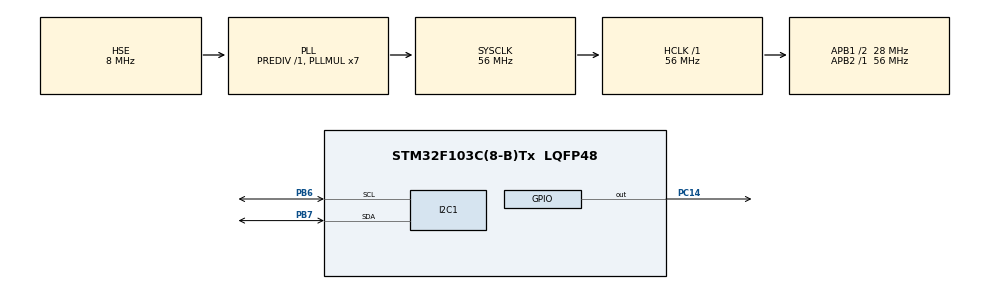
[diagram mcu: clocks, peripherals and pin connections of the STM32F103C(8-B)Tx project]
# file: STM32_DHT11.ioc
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Mcu.Family=STM32F1
Mcu.Name=STM32F103C(8-B)Tx
Mcu.Package=LQFP48
NVIC.PriorityGroup=NVIC_PRIORITYGROUP_4
PA13.Mode=Serial_Wire
PA13.Signal=SYS_JTMS-SWDIO
PA14.Mode=Serial_Wire
PA14.Signal=SYS_JTCK-SWCLK
PB6.Mode=I2C
PB6.Signal=I2C1_SCL
PB7.Mode=I2C
PB7.Signal=I2C1_SDA
PC14-OSC32_IN.GPIO_Speed=GPIO_SPEED_FREQ_HIGH
PC14-OSC32_IN.Signal=GPIO_Output
PD0-OSC_IN.Mode=HSE-External-Oscillator
PD0-OSC_IN.Signal=RCC_OSC_IN
PD1-OSC_OUT.Mode=HSE-External-Oscillator
PD1-OSC_OUT.Signal=RCC_OSC_OUT
ProjectManager.HeapSize=0x200
ProjectManager.StackSize=0x400
ProjectManager.TargetToolchain=MDK-ARM V5.27
RCC.AHBFreq_Value=56000000
RCC.APB1CLKDivider=RCC_HCLK_DIV2
RCC.APB1Freq_Value=28000000
RCC.APB1TimFreq_Value=56000000
RCC.APB2Freq_Value=56000000
RCC.APB2TimFreq_Value=56000000
RCC.HCLKFreq_Value=56000000
RCC.PLLMUL=RCC_PLL_MUL7
RCC.PLLSourceVirtual=RCC_PLLSOURCE_HSE
RCC.SYSCLKFreq_VALUE=56000000
RCC.SYSCLKSource=RCC_SYSCLKSOURCE_PLLCLK
RCC.USBFreq_Value=56000000
TIM2.AutoReloadPreload=TIM_AUTORELOAD_PRELOAD_DISABLE
TIM2.Period=0xFFFF
TIM2.Prescaler=56-1
VP_TIM2_VS_ClockSourceINT.Mode=Internal
board=custom

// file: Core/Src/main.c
/* USER CODE BEGIN Header */
/**
  ******************************************************************************
  * @file           : main.c
  * @brief          : Main program body
  ******************************************************************************
  * @attention
  *
  * <h2><center>&copy; Copyright (c) 2020 STMicroelectronics.
  * All rights reserved.</center></h2>
  *
  * This software component is licensed by ST under BSD 3-Clause license,
  * the "License"; You may not use this file except in compliance with the
  * License. You may obtain a copy of the License at:
  *                        opensource.org/licenses/BSD-3-Clause
  *
  ******************************************************************************
  */
/* USER CODE END Header */

#include "main.h"

/* USER CODE BEGIN Includes */
#include "stdio.h"
#include "i2c-lcd.h"
/* USER CODE END Includes */

I2C_HandleTypeDef hi2c1;

TIM_HandleTypeDef htim2;

void SystemClock_Config(void);
static void MX_GPIO_Init(void);
static void MX_TIM2_Init(void);
static void MX_I2C1_Init(void);
/* USER CODE BEGIN PFP */
void delay (uint16_t times)
{
	/* change your code here for the delay in microseconds */
	__HAL_TIM_SET_COUNTER(&htim2, 0);
	while ((__HAL_TIM_GET_COUNTER(&htim2))<times);
}
uint8_t Rh_byte1, Rh_byte2, Temp_byte1, Temp_byte2;
uint16_t SUM, RH, TEMP;
uint8_t Presence = 0;
int Temperature = 0;
int Humidity = 0;
char str1[20];
char str2[20];
#define DHT11_PORT GPIOC
#define DHT11_PIN GPIO_PIN_14
void Set_Pin_Output (GPIO_TypeDef *GPIOx, uint16_t GPIO_Pin)
{
	GPIO_InitTypeDef GPIO_InitStruct = {0};
	GPIO_InitStruct.Pin = GPIO_Pin;
	GPIO_InitStruct.Mode = GPIO_MODE_OUTPUT_PP;
	GPIO_InitStruct.Speed = GPIO_SPEED_FREQ_HIGH;
	HAL_GPIO_Init(GPIOx, &GPIO_InitStruct);
}
void Set_Pin_Input (GPIO_TypeDef *GPIOx, uint16_t GPIO_Pin)
{
	GPIO_InitTypeDef GPIO_InitStruct = {0};
	GPIO_InitStruct.Pin = GPIO_Pin;
	GPIO_InitStruct.Mode = GPIO_MODE_INPUT;
	GPIO_InitStruct.Pull = GPIO_NOPULL;
	HAL_GPIO_Init(GPIOx, &GPIO_InitStruct);
}
/* USER CODE END PFP */

/* USER CODE BEGIN 0 */
void DHT11_Start (void)
{
	Set_Pin_Output (DHT11_PORT, DHT11_PIN);  // set the pin as output
	HAL_GPIO_WritePin (DHT11_PORT, DHT11_PIN, GPIO_PIN_SET);
	delay(1000);//1ms

	HAL_GPIO_WritePin (DHT11_PORT, DHT11_PIN, GPIO_PIN_RESET);   // pull the pin low
	delay (18000);   // wait for 18ms
    HAL_GPIO_WritePin (DHT11_PORT, DHT11_PIN, GPIO_PIN_SET);   // pull the pin high
	delay (20);   // wait for 20us
	Set_Pin_Input(DHT11_PORT, DHT11_PIN);    // set as input
}
uint8_t DHT11_Check_Response (void)
{
	uint8_t Response = 0;
	delay (40);
	if (!(HAL_GPIO_ReadPin (DHT11_PORT, DHT11_PIN)))
	{
		delay (80);
		if ((HAL_GPIO_ReadPin (DHT11_PORT, DHT11_PIN))) Response = 1;
		else Response = -1; // 255
	}
	while ((HAL_GPIO_ReadPin (DHT11_PORT, DHT11_PIN)));		// wait for the pin to go low

	return Response;
}
uint8_t DHT11_Read (void)
{
	uint8_t k,l;
	for (l=0;l<8;l++)
	{
		while (!(HAL_GPIO_ReadPin (DHT11_PORT, DHT11_PIN)));   // wait for the pin to go high
		delay (40);   // wait for 40 us
		if (!(HAL_GPIO_ReadPin (DHT11_PORT, DHT11_PIN)))   // if the pin is low
		{
			k&= ~(1<<(7-l)); 			// write 0
		}
		else k|= (1<<(7-l));  // if the pin is high, write 1
		while ((HAL_GPIO_ReadPin (DHT11_PORT, DHT11_PIN)));		// wait for the pin to go low
	}
	return k;
}
/* USER CODE END 0 */

int main(void)
{

  /* MCU Configuration--------------------------------------------------------*/

  /* Reset of all peripherals, Initializes the Flash interface and the Systick. */
  HAL_Init();

  /* Configure the system clock */
  SystemClock_Config();

  /* Initialize all configured peripherals */
  MX_GPIO_Init();
  MX_TIM2_Init();
  MX_I2C1_Init();
  /* USER CODE BEGIN 2 */
HAL_TIM_Base_Start(&htim2);
	lcd_init();
	lcd_send_string("INITIALISING>>>>>");
	HAL_Delay(2000);
	lcd_clear_display ();
	HAL_Delay(20);
  /* USER CODE END 2 */

  /* Infinite loop */
  while (1)
  {

    /* USER CODE BEGIN 3 */

		DHT11_Start();
	Presence = DHT11_Check_Response();
		if(Presence==1)
			{
		Rh_byte1 = DHT11_Read();
	  Rh_byte2 = DHT11_Read ();
	  Temp_byte1 = DHT11_Read ();
	  Temp_byte2 = DHT11_Read ();
	  SUM = DHT11_Read();
				TEMP = Temp_byte1;
	  RH = Rh_byte1;
				}
			HAL_Delay(500);
					Temp_byte2=(int) Temp_byte2;
	  Temperature = (int) TEMP;
	  Humidity = (int) RH;
				sprintf (str1, "T:%0.2d.%0.2d'C  ", Temperature,Temp_byte2);
				sprintf (str2, "H:%0.1d", Humidity);
				lcd_goto_XY(0,0);
				lcd_send_string(str1);
				lcd_goto_XY(0,11);
				lcd_send_string(str2);
				lcd_goto_XY(0,15);
				lcd_send_data('%');
				HAL_Delay(3000);
  }
  /* USER CODE END 3 */
}

void SystemClock_Config(void)
{
  RCC_OscInitTypeDef RCC_OscInitStruct = {0};
  RCC_ClkInitTypeDef RCC_ClkInitStruct = {0};

  /** Initializes the CPU, AHB and APB busses clocks
  */
  RCC_OscInitStruct.OscillatorType = RCC_OSCILLATORTYPE_HSE;
  RCC_OscInitStruct.HSEState = RCC_HSE_ON;
  RCC_OscInitStruct.HSEPredivValue = RCC_HSE_PREDIV_DIV1;
  RCC_OscInitStruct.HSIState = RCC_HSI_ON;
  RCC_OscInitStruct.PLL.PLLState = RCC_PLL_ON;
  RCC_OscInitStruct.PLL.PLLSource = RCC_PLLSOURCE_HSE;
  RCC_OscInitStruct.PLL.PLLMUL = RCC_PLL_MUL7;
  if (HAL_RCC_OscConfig(&RCC_OscInitStruct) != HAL_OK)
  {
    Error_Handler();
  }
  /** Initializes the CPU, AHB and APB busses clocks
  */
  RCC_ClkInitStruct.ClockType = RCC_CLOCKTYPE_HCLK|RCC_CLOCKTYPE_SYSCLK
                              |RCC_CLOCKTYPE_PCLK1|RCC_CLOCKTYPE_PCLK2;
  RCC_ClkInitStruct.SYSCLKSource = RCC_SYSCLKSOURCE_PLLCLK;
  RCC_ClkInitStruct.AHBCLKDivider = RCC_SYSCLK_DIV1;
  RCC_ClkInitStruct.APB1CLKDivider = RCC_HCLK_DIV2;
  RCC_ClkInitStruct.APB2CLKDivider = RCC_HCLK_DIV1;

  if (HAL_RCC_ClockConfig(&RCC_ClkInitStruct, FLASH_LATENCY_2) != HAL_OK)
  {
    Error_Handler();
  }
}

static void MX_I2C1_Init(void)
{

  hi2c1.Instance = I2C1;
  hi2c1.Init.ClockSpeed = 100000;
  hi2c1.Init.DutyCycle = I2C_DUTYCYCLE_2;
  hi2c1.Init.OwnAddress1 = 0;
  hi2c1.Init.AddressingMode = I2C_ADDRESSINGMODE_7BIT;
  hi2c1.Init.DualAddressMode = I2C_DUALADDRESS_DISABLE;
  hi2c1.Init.OwnAddress2 = 0;
  hi2c1.Init.GeneralCallMode = I2C_GENERALCALL_DISABLE;
  hi2c1.Init.NoStretchMode = I2C_NOSTRETCH_DISABLE;
  if (HAL_I2C_Init(&hi2c1) != HAL_OK)
  {
    Error_Handler();
  }

}

static void MX_TIM2_Init(void)
{

  TIM_ClockConfigTypeDef sClockSourceConfig = {0};
  TIM_MasterConfigTypeDef sMasterConfig = {0};

  htim2.Instance = TIM2;
  htim2.Init.Prescaler = 56-1;
  htim2.Init.CounterMode = TIM_COUNTERMODE_UP;
  htim2.Init.Period = 0xFFFF;
  htim2.Init.ClockDivision = TIM_CLOCKDIVISION_DIV1;
  htim2.Init.AutoReloadPreload = TIM_AUTORELOAD_PRELOAD_DISABLE;
  if (HAL_TIM_Base_Init(&htim2) != HAL_OK)
  {
    Error_Handler();
  }
  sClockSourceConfig.ClockSource = TIM_CLOCKSOURCE_INTERNAL;
  if (HAL_TIM_ConfigClockSource(&htim2, &sClockSourceConfig) != HAL_OK)
  {
    Error_Handler();
  }
  sMasterConfig.MasterOutputTrigger = TIM_TRGO_RESET;
  sMasterConfig.MasterSlaveMode = TIM_MASTERSLAVEMODE_DISABLE;
  if (HAL_TIMEx_MasterConfigSynchronization(&htim2, &sMasterConfig) != HAL_OK)
  {
    Error_Handler();
  }

}

static void MX_GPIO_Init(void)
{
  GPIO_InitTypeDef GPIO_InitStruct = {0};

  /* GPIO Ports Clock Enable */
  __HAL_RCC_GPIOC_CLK_ENABLE();
  __HAL_RCC_GPIOD_CLK_ENABLE();
  __HAL_RCC_GPIOA_CLK_ENABLE();
  __HAL_RCC_GPIOB_CLK_ENABLE();

  /*Configure GPIO pin Output Level */
  HAL_GPIO_WritePin(GPIOC, GPIO_PIN_14, GPIO_PIN_RESET);

  /*Configure GPIO pin : PC14 */
  GPIO_InitStruct.Pin = GPIO_PIN_14;
  GPIO_InitStruct.Mode = GPIO_MODE_OUTPUT_PP;
  GPIO_InitStruct.Pull = GPIO_NOPULL;
  GPIO_InitStruct.Speed = GPIO_SPEED_FREQ_HIGH;
  HAL_GPIO_Init(GPIOC, &GPIO_InitStruct);

}

void Error_Handler(void)
{
}

/************************ (C) COPYRIGHT STMicroelectronics *****END OF FILE****/
